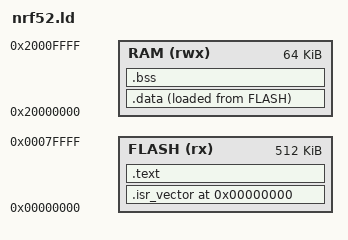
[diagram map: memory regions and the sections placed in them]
ENTRY(Reset_Handler)

MEMORY
{
  FLASH (rx) : ORIGIN = 0x00000000, LENGTH = 512K
  RAM (rwx)  : ORIGIN = 0x20000000, LENGTH = 64K
}

/* _estack = конец RAM = вершина стека */
_estack = ORIGIN(RAM) + LENGTH(RAM);

SECTIONS
{
  . = ORIGIN(FLASH);

  .isr_vector :
  {
    KEEP(*(.isr_vector))
  } > FLASH

  .text :
  {
    *(.text*)
    *(.rodata*)
  } > FLASH

  .data :
  {
    _sdata = .;
    *(.data*)
    _edata = .;
  } > RAM AT > FLASH

  _sidata = LOADADDR(.data);

  .bss :
  {
    _sbss = .;
    *(.bss*)
    *(COMMON)
    _ebss = .;
  } > RAM
}
